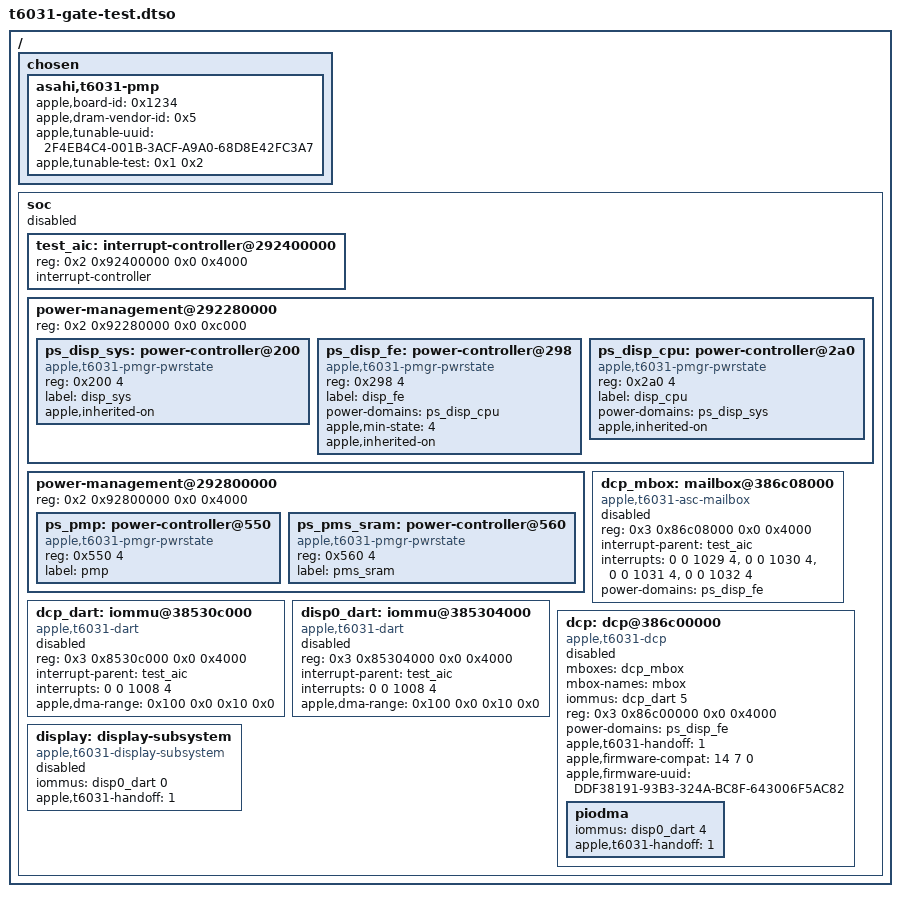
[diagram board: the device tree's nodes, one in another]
// SPDX-License-Identifier: GPL-2.0+ OR MIT
/*
 * Test device tree for the display gate KUnit test: the T6031 display
 * nodes of t6031-dcp.dtsi with the boot loader's handoff applied, the power
 * states they hang from, and PMP values. The values are made up: only their
 * presence and the PMP image UUID matter to the gate.
 *
 * /soc is disabled, so no device is created for any of these nodes.
 */

/dts-v1/;
/plugin/;

/ {
	fragment@0 {
		target-path = "/";

		__overlay__ {
			chosen {
				asahi,t6031-pmp {
					apple,board-id = <0x1234>;
					apple,dram-vendor-id = <0x5>;
					apple,tunable-uuid = "2F4EB4C4-001B-3ACF-A9A0-68D8E42FC3A7";
					apple,tunable-test = <0x1 0x2>;
				};
			};

			soc {
				#address-cells = <2>;
				#size-cells = <2>;
				status = "disabled";

				test_aic: interrupt-controller@292400000 {
					reg = <0x2 0x92400000 0x0 0x4000>;
					interrupt-controller;
					#interrupt-cells = <4>;
				};

				power-management@292280000 {
					reg = <0x2 0x92280000 0x0 0xc000>;
					#address-cells = <1>;
					#size-cells = <1>;

					ps_disp_sys: power-controller@200 {
						compatible = "apple,t6031-pmgr-pwrstate", "apple,t8103-pmgr-pwrstate";
						reg = <0x200 4>;
						#power-domain-cells = <0>;
						label = "disp_sys";
						apple,inherited-on;
					};

					ps_disp_fe: power-controller@298 {
						compatible = "apple,t6031-pmgr-pwrstate", "apple,t8103-pmgr-pwrstate";
						reg = <0x298 4>;
						#power-domain-cells = <0>;
						label = "disp_fe";
						power-domains = <&ps_disp_cpu>;
						apple,min-state = <4>;
						apple,inherited-on;
					};

					ps_disp_cpu: power-controller@2a0 {
						compatible = "apple,t6031-pmgr-pwrstate", "apple,t8103-pmgr-pwrstate";
						reg = <0x2a0 4>;
						#power-domain-cells = <0>;
						label = "disp_cpu";
						power-domains = <&ps_disp_sys>;
						apple,inherited-on;
					};
				};

				power-management@292800000 {
					reg = <0x2 0x92800000 0x0 0x4000>;
					#address-cells = <1>;
					#size-cells = <1>;

					ps_pmp: power-controller@550 {
						compatible = "apple,t6031-pmgr-pwrstate", "apple,t8103-pmgr-pwrstate";
						reg = <0x550 4>;
						#power-domain-cells = <0>;
						label = "pmp";
					};

					ps_pms_sram: power-controller@560 {
						compatible = "apple,t6031-pmgr-pwrstate", "apple,t8103-pmgr-pwrstate";
						reg = <0x560 4>;
						#power-domain-cells = <0>;
						label = "pms_sram";
					};
				};

				dcp_mbox: mailbox@386c08000 {
					compatible = "apple,t6031-asc-mailbox", "apple,asc-mailbox-v4";
					reg = <0x3 0x86c08000 0x0 0x4000>;
					interrupt-parent = <&test_aic>;
					interrupts = <0 0 1029 4>, <0 0 1030 4>, <0 0 1031 4>, <0 0 1032 4>;
					interrupt-names = "send-empty", "send-not-empty",
							  "recv-empty", "recv-not-empty";
					power-domains = <&ps_disp_fe>;
					#mbox-cells = <0>;
					status = "disabled";
				};

				dcp_dart: iommu@38530c000 {
					compatible = "apple,t6031-dart", "apple,t8110-dart";
					reg = <0x3 0x8530c000 0x0 0x4000>;
					interrupt-parent = <&test_aic>;
					interrupts = <0 0 1008 4>;
					#iommu-cells = <1>;
					apple,dma-range = <0x100 0x0 0x10 0x0>;
					status = "disabled";
				};

				disp0_dart: iommu@385304000 {
					compatible = "apple,t6031-dart", "apple,t8110-dart";
					reg = <0x3 0x85304000 0x0 0x4000>;
					interrupt-parent = <&test_aic>;
					interrupts = <0 0 1008 4>;
					#iommu-cells = <1>;
					apple,dma-range = <0x100 0x0 0x10 0x0>;
					status = "disabled";
				};

				dcp: dcp@386c00000 {
					compatible = "apple,t6031-dcp";
					mboxes = <&dcp_mbox>;
					mbox-names = "mbox";
					iommus = <&dcp_dart 5>;
					reg-names = "coproc";
					reg = <0x3 0x86c00000 0x0 0x4000>;
					power-domains = <&ps_disp_fe>;
					#address-cells = <2>;
					#size-cells = <2>;
					status = "disabled";
					apple,t6031-handoff = <1>;
					apple,firmware-compat = <14 7 0>;
					apple,firmware-uuid = "DDF38191-93B3-324A-BC8F-643006F5AC82";

					piodma {
						iommus = <&disp0_dart 4>;
						apple,t6031-handoff = <1>;
					};
				};

				display: display-subsystem {
					compatible = "apple,t6031-display-subsystem";
					iommus = <&disp0_dart 0>;
					status = "disabled";
					apple,t6031-handoff = <1>;
				};
			};
		};
	};
};
